# BAT32A237 register map
Vendor: CMS; Series: BAT32A237; File version: 1.2
CPU: CM0+ r0p1, little endian, MPU, no FPU, VTOR, 2 interrupt priority bits
Registers are 8-bit, read-write, reset 0x0 unless marked. A register's access mark holds for its fields unless they carry their own. Offsets are from the block's base; [hi:lo] are bit positions; {n}, {i} and the like mark numbered series.

## DIV — Hardware divider
Base 0x40080000
0x00 DIVIDEND 32-bit
0x04 DIVISOR 32-bit
0x08 QUOTIENT 32-bit ro
0x0C REMAINDER 32-bit ro
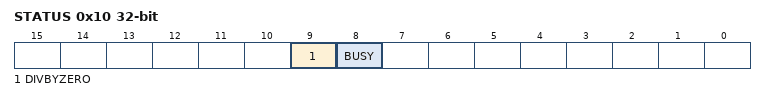
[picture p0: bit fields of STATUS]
0x10 STATUS 32-bit ro
  [9] DIVBYZERO — divider zero flag
  [8] BUSY — divider busy flag

## TMA — General Purpose Timer A
Base 0x40042240
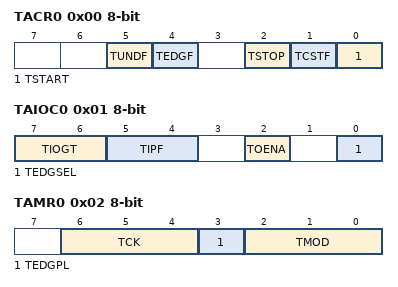
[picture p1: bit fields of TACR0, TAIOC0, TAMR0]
0x00 TACR0 — Timer control register 0
  [5] TUNDF — Timer underflow flag
  [4] TEDGF — Active edge flag
  [2] TSTOP — Timer count forced stop
  [1] TCSTF — Timer count status flag
  [0] TSTART — Timer count start
0x01 TAIOC0 — Timer I/O control register 0
  [7:6] TIOGT — TAIO count control
  [5:4] TIPF — TAIO input filter select
  [2] TOENA — TAO output enable
  [0] TEDGSEL — I/O polarity switch
0x02 TAMR0 — Timer mode register 0
  [6:4] TCK — Timer count source select
  [3] TEDGPL — TAIO edge polarity select
  [2:0] TMOD — Operation mode select
0x03 TAISR0 — Timer event pin select register 0
  [2:0] RCCPSEL — Timer output signal select
0xC0 TA0 16-bit reset 0xFFFF — Timer counter register 0

## TMB — General Purpose Timer B
Base 0x40042650
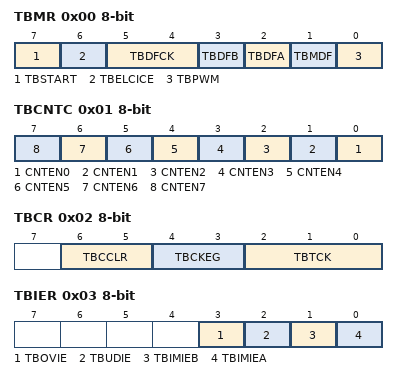
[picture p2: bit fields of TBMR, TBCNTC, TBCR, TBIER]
0x00 TBMR — Timer mode register
  [7] TBSTART — Timer count start
  [6] TBELCICE — EVENTC input capture request select
  [5:4] TBDFCK — Digital filter function clock select
  [3] TBDFB — Digital filer function select for TBIO1 pin
  [2] TBDFA — Digital filer function select for TBIO0 pin
  [1] TBMDF — Phase counting mode select
  [0] TBPWM — PWM mode select
0x01 TBCNTC — Timer count control register
  [n] CNTEN{n} (n=0..7) — counter enable {n}
0x02 TBCR — Timer control register
  [6:5] TBCCLR — TB register clear source select
  [4:3] TBCKEG — External clock active edge select
  [2:0] TBTCK — Count source select
0x03 TBIER — Timer interrupt enable register
  [3] TBOVIE — Overflow interrupt enable
  [2] TBUDIE — Underflow interrupt enable
  [1] TBIMIEB — Input-capture/compare-match interrupt enable B
  [0] TBIMIEA — Input-capture/compare-match interrupt enable A
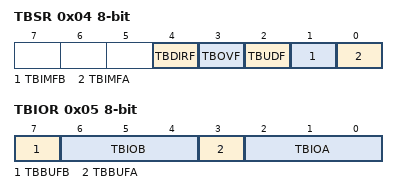
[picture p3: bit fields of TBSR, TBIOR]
0x04 TBSR — Timer status enable register
  [4] TBDIRF — Count direction flag
  [3] TBOVF — Overflow flag
  [2] TBUDF — Underflow flag
  [1] TBIMFB — Input-capture/compare-match flag B
  [0] TBIMFA — Input-capture/compare-match flag A
0x05 TBIOR — Timer I/O control register
  [7] TBBUFB — TBGRD register function select
  [6:4] TBIOB — TBGRB mode select and control
  [3] TBBUFA — TBGRC register function select
  [2:0] TBIOA — TBGRA mode select and control
0x06 TB 16-bit — Timer counter register
0x08 TBGR{x} (x=A,B,C,D; step 0x2) 16-bit reset 0xFFFF — Timer general register {x}

## TMC — General Purpose Timer C
Base 0x40042C50
0x00 TC 16-bit — Timer counter register
0x02 TCBUF 16-bit — Timer count buffer register
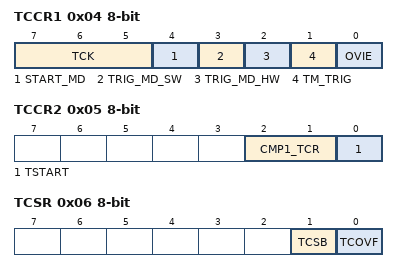
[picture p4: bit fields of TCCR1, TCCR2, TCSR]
0x04 TCCR1 — Timer control register 1
  [7:5] TCK — Selects count source
  [4] START_MD — Selects count start source
  [3] TRIG_MD_SW — Signal for enabling TC counter reset by software
  [2] TRIG_MD_HW — Selects operation in a count mode selected by a trigger from timer M
  [1] TM_TRIG — Selects a hardware start trigger from timer M
  [0] OVIE — Enables overflow interrupt
0x05 TCCR2 — Timer control register 2
  [2:1] CMP1_TCR — Selects operation to be performed when a trigger is generated from comparator 1
  [0] TSTART — counter start
0x06 TCSR — Timer status register
  [1] TCSB — Counter status flag
  [0] TCOVF — Overflow status of TC counter

## RTC — Real-Time clock
Base 0x40044F00
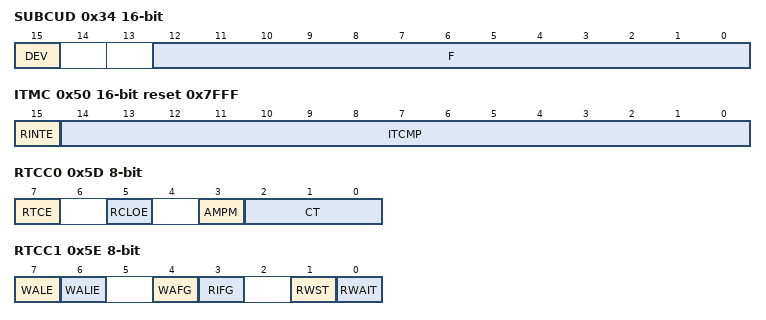
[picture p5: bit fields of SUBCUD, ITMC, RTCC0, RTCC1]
0x34 SUBCUD 16-bit — Watch error correction register
  [15] DEV — watch error correction timing
  [12:0] F — watch error correction value
0x50 ITMC 16-bit reset 0x7FFF — 15-bit interval timer control register
  [15] RINTE — 15-bit interval timer operation control
  [14:0] ITCMP — 15-bit interval timer compare value
0x52 SEC (reset mask 0x7F) — Second count register
0x53 MIN (reset mask 0x7F) — Minute count register
0x54 HOUR reset 0x12 (reset mask 0x3F) — Hour count register
0x55 WEEK (reset mask 0x7) — Week count register
0x56 DAY reset 0x1 (reset mask 0x3F) — Day count register
0x57 MONTH reset 0x1 (reset mask 0x1F) — Month count register
0x58 YEAR — Year count register
0x5A ALARMWM (reset mask 0x7F) — Alarm minute register
0x5B ALARMWH reset 0x12 (reset mask 0x3F) — Alarm hour register
0x5C ALARMWW (reset mask 0x3F) — Alarm week register
0x5D RTCC0 — Real-time clock control register 0
  [7] RTCE — Real-time clock operation control
  [5] RCLOE — RTC1HZ pin output enable
  [3] AMPM — Selection of 12-/24-hour system
  [2:0] CT — Constant-period interrupt (INTRTC) selection
0x5E RTCC1 — Real-time clock control register 1
  [7] WALE — Alarm operation control
  [6] WALIE — Control of alarm interrupt (INTRTC) function operation
  [4] WAFG — Alarm detection status flag
  [3] RIFG — Constant-period interrupt status flag
  [1] RWST — Wait status flag of real-time clock
  [0] RWAIT — Wait control of real-time clock

## Notices in the file
Copyright (C) 2012-2014 ARM Limited. All rights reserved.
Purpose: System Viewer Description (SVD) Example (Schema Version 1.1)
This is a description of a none-existent and incomplete device
for demonstration purposes only.
Redistribution and use in source and binary forms, with or without
modification, are permitted provided that the following conditions are met:
- Redistributions of source code must retain the above copyright
notice, this list of conditions and the following disclaimer.
- Redistributions in binary form must reproduce the above copyright
notice, this list of conditions and the following disclaimer in the
documentation and/or other materials provided with the distribution.
- Neither the name of ARM nor the names of its contributors may be used
to endorse or promote products derived from this software without
specific prior written permission.
THIS SOFTWARE IS PROVIDED BY THE COPYRIGHT HOLDERS AND CONTRIBUTORS "AS IS"
AND ANY EXPRESS OR IMPLIED WARRANTIES, INCLUDING, BUT NOT LIMITED TO, THE
IMPLIED WARRANTIES OF MERCHANTABILITY AND FITNESS FOR A PARTICULAR PURPOSE
ARE DISCLAIMED. IN NO EVENT SHALL COPYRIGHT HOLDERS AND CONTRIBUTORS BE
LIABLE FOR ANY DIRECT, INDIRECT, INCIDENTAL, SPECIAL, EXEMPLARY, OR
CONSEQUENTIAL DAMAGES (INCLUDING, BUT NOT LIMITED TO, PROCUREMENT OF
SUBSTITUTE GOODS OR SERVICES; LOSS OF USE, DATA, OR PROFITS; OR BUSINESS
INTERRUPTION) HOWEVER CAUSED AND ON ANY THEORY OF LIABILITY, WHETHER IN
CONTRACT, STRICT LIABILITY, OR TORT (INCLUDING NEGLIGENCE OR OTHERWISE)
ARISING IN ANY WAY OUT OF THE USE OF THIS SOFTWARE, EVEN IF ADVISED OF THE
POSSIBILITY OF SUCH DAMAGE.
